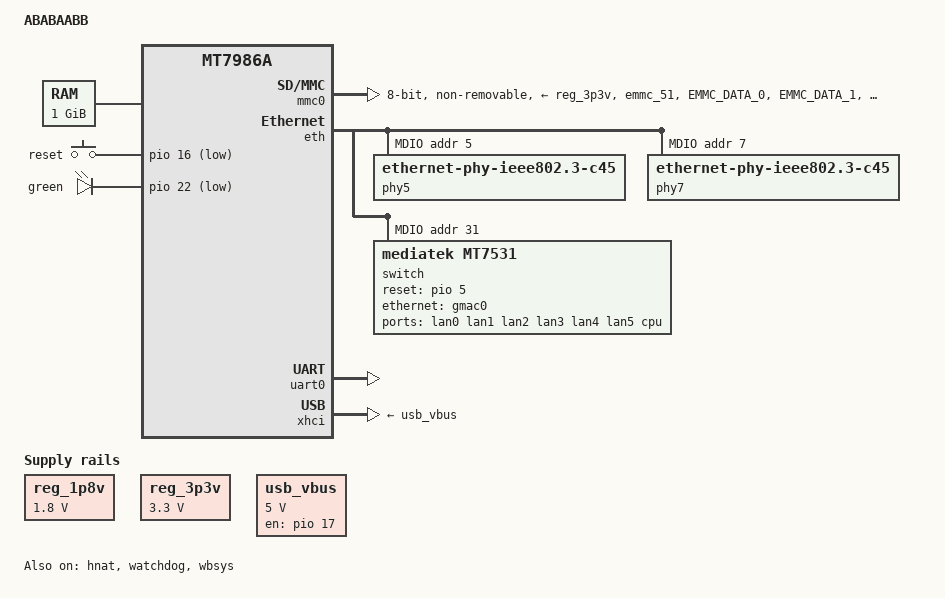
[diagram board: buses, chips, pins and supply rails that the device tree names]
// SPDX-License-Identifier: GPL-2.0-or-later OR MIT

/dts-v1/;
#include "mt7986a.dtsi"
#include "mt7986a-pinctrl.dtsi"
#include <dt-bindings/input/input.h>
#include <dt-bindings/gpio/gpio.h>
#include <dt-bindings/leds/common.h>

/ {
	model = "ABABAABB";
	compatible = "ccc,ddd", "mediatek,mt7986a-emmc-rfb";

	aliases {
		led-boot = &green_led;
		led-failsafe = &green_led;
		led-running = &green_led;
		led-upgrade = &green_led;
	};

	chosen {
		bootargs = "console=ttyS0,115200n1 loglevel=8 \
			    earlycon=uart8250,mmio32,0x11002000 \
			    root=PARTLABEL=rootfs rootwait rootfstype=squashfs,f2fs";
	};

	memory {
		reg = <0 0x40000000 0 0x40000000>;
	};

	gpio-keys {
		compatible = "gpio-keys";

		button-reset {
			label = "reset";
			linux,code = <KEY_RESTART>;
			gpios = <&pio 16 GPIO_ACTIVE_LOW>;
		};
	};

	gpio-leds {
		compatible = "gpio-leds";
		green_led: green_led {
			label = "green";
			gpios = <&pio 22 GPIO_ACTIVE_LOW>;
		};
	};

	reg_1p8v: regulator-1p8v {
		compatible = "regulator-fixed";
		regulator-name = "fixed-1.8V";
		regulator-min-microvolt = <1800000>;
		regulator-max-microvolt = <1800000>;
		regulator-boot-on;
		regulator-always-on;
	};

	reg_3p3v: regulator-3p3v {
		compatible = "regulator-fixed";
		regulator-name = "fixed-3.3V";
		regulator-min-microvolt = <3300000>;
		regulator-max-microvolt = <3300000>;
		regulator-boot-on;
		regulator-always-on;
	};
	
	usb_vbus: regulator-usb-vbus {
		compatible = "regulator-fixed";
		regulator-name = "usb_vbus";
		regulator-min-microvolt = <5000000>;
		regulator-max-microvolt = <5000000>;
		gpios = <&pio 17 GPIO_ACTIVE_HIGH>;
		enable-active-high;
		regulator-boot-on;
	};
	
};

&mmc0 {
	bus-width = <8>;
	cap-mmc-highspeed;
	hs400-ds-delay = <0x14014>;
	max-frequency = <200000000>;
	mmc-hs200-1_8v;
	mmc-hs400-1_8v;
	no-sd;
	no-sdio;
	non-removable;
	pinctrl-names = "default", "state_uhs";
	pinctrl-0 = <&mmc0_pins_default>;
	pinctrl-1 = <&mmc0_pins_uhs>;
	vmmc-supply = <&reg_3p3v>;
	vqmmc-supply = <&reg_1p8v>;
	status = "okay";
};

&pio {
	mmc0_pins_default: mmc0-pins-default {
		mux {
			function = "flash";
			groups = "emmc_51";
		};
		conf-cmd-dat {
			pins = "EMMC_DATA_0", "EMMC_DATA_1", "EMMC_DATA_2",
			       "EMMC_DATA_3", "EMMC_DATA_4", "EMMC_DATA_5",
			       "EMMC_DATA_6", "EMMC_DATA_7", "EMMC_CMD";
			input-enable;
			drive-strength = <MTK_DRIVE_4mA>;
			mediatek,pull-up-adv = <1>;
		};
		conf-clk {
			pins = "EMMC_CK";
			drive-strength = <MTK_DRIVE_6mA>;
			mediatek,pull-down-adv = <2>;
		};
		conf-ds {
			pins = "EMMC_DSL";
			mediatek,pull-down-adv = <2>;
		};
		conf-rst {
			pins = "EMMC_RSTB";
			drive-strength = <MTK_DRIVE_4mA>;
			mediatek,pull-up-adv = <1>;
		};
	};

	mmc0_pins_uhs: mmc0-uhs-pins {
		mux {
			function = "flash";
			groups = "emmc_51";
		};
		conf-cmd-dat {
			pins = "EMMC_DATA_0", "EMMC_DATA_1", "EMMC_DATA_2",
			       "EMMC_DATA_3", "EMMC_DATA_4", "EMMC_DATA_5",
			       "EMMC_DATA_6", "EMMC_DATA_7", "EMMC_CMD";
			input-enable;
			drive-strength = <MTK_DRIVE_4mA>;
			mediatek,pull-up-adv = <1>;
		};
		conf-clk {
			pins = "EMMC_CK";
			drive-strength = <MTK_DRIVE_6mA>;
			mediatek,pull-down-adv = <2>;
		};
		conf-ds {
			pins = "EMMC_DSL";
			mediatek,pull-down-adv = <2>;
		};
		conf-rst {
			pins = "EMMC_RSTB";
			drive-strength = <MTK_DRIVE_4mA>;
			mediatek,pull-up-adv = <1>;
		};
	};

	wf_2g_5g_pins: wf-2g-5g-pins {
		mux {
			function = "wifi";
			groups = "wf_2g", "wf_5g";
		};
		conf {
			pins = "WF0_HB1", "WF0_HB2", "WF0_HB3", "WF0_HB4",
			       "WF0_HB0", "WF0_HB0_B", "WF0_HB5", "WF0_HB6",
			       "WF0_HB7", "WF0_HB8", "WF0_HB9", "WF0_HB10",
			       "WF0_TOP_CLK", "WF0_TOP_DATA", "WF1_HB1",
			       "WF1_HB2", "WF1_HB3", "WF1_HB4", "WF1_HB0",
			       "WF1_HB5", "WF1_HB6", "WF1_HB7", "WF1_HB8",
			       "WF1_TOP_CLK", "WF1_TOP_DATA";
			drive-strength = <MTK_DRIVE_4mA>;
		};
	};
};
&eth {
	status = "okay";

	gmac0: mac@0 {
		compatible = "mediatek,eth-mac";
		reg = <0>;
		phy-mode = "2500base-x";
		ext-phy-reg = <5>;
		ext-phy-reset-gpios = <&pio 48 0>;
		fixed-link {
			speed = <2500>;
			full-duplex;
			pause;
		};	
	};

	gmac1: mac@1 {
		compatible = "mediatek,eth-mac";
		reg = <1>;
		phy-mode = "2500base-x";
		ext-phy-reg = <7>;
		ext-phy-reset-gpios = <&pio 6 0>;	
		fixed-link {
			speed = <2500>;
			full-duplex;
			pause;
		};
	};

	mdio: mdio-bus {
		#address-cells = <1>;
		#size-cells = <0>;

		phy5: phy@5 {
			compatible = "ethernet-phy-ieee802.3-c45";
			reg = <5>;
		};
		
		phy7: phy@7 {
			compatible = "ethernet-phy-ieee802.3-c45";
			reg = <7>;
		};


		switch@0 {
			compatible = "mediatek,mt7531";
			reg = <31>;
			reset-gpios = <&pio 5 0>;

			ports {
				#address-cells = <1>;
				#size-cells = <0>;

				port@0 {
					reg = <0>;
					label = "lan0";
				};

				port@1 {
					reg = <1>;
					label = "lan1";
				};

				port@2 {
					reg = <2>;
					label = "lan2";
				};

				port@3 {
					reg = <3>;
					label = "lan3";
				};

				port@4 {
					reg = <4>;
					label = "lan4";
				};

				port@5 {
					reg = <5>;
					label = "lan5";
					phy-mode = "2500base-x";

					fixed-link {
						speed = <2500>;
						full-duplex;
						pause;
					};
				};

				port@6 {
					reg = <6>;
					label = "cpu";
					ethernet = <&gmac0>;
					phy-mode = "2500base-x";

					fixed-link {
						speed = <2500>;
						full-duplex;
						pause;
					};
				};
			};
		};
	};
};

&hnat {
	mtketh-wan = "eth1";
	mtketh-lan = "lan";
	mtketh-max-gmac = <2>;
	status = "okay";
};

&uart0 {
	status = "okay";
};

&watchdog {
	status = "okay";
};

&wbsys {
	pinctrl-names = "default";
	pinctrl-0 = <&wf_2g_5g_pins>;
	status = "okay";
};

&xhci {
 	vusb33-supply = <&reg_3p3v>;
 	vbus-supply = <&usb_vbus>;
 	status = "okay";
};

